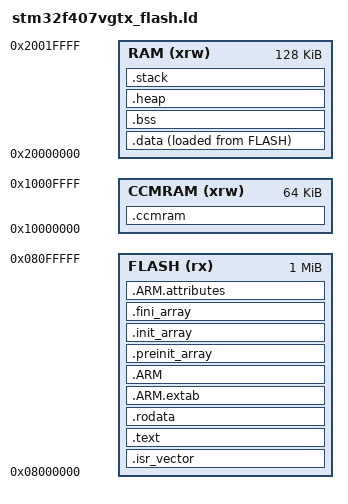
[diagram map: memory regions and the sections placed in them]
/*
 * Linker script for STM32F407VGTX (STM32F4 Discovery).
 *   FLASH: 1024 KB @ 0x08000000
 *   RAM:   128 KB @ 0x20000000
 *   CCMRAM: 64 KB @ 0x10000000
 */
ENTRY(Reset_Handler)

_estack = ORIGIN(RAM) + LENGTH(RAM);

_Min_Heap_Size = 0x200;
_Min_Stack_Size = 0x800;

MEMORY
{
  RAM    (xrw) : ORIGIN = 0x20000000, LENGTH = 128K
  CCMRAM (xrw) : ORIGIN = 0x10000000, LENGTH = 64K
  FLASH  (rx)  : ORIGIN = 0x08000000, LENGTH = 1024K
}

SECTIONS
{
  .isr_vector :
  {
    . = ALIGN(4);
    KEEP(*(.isr_vector))
    . = ALIGN(4);
  } >FLASH

  .text :
  {
    . = ALIGN(4);
    *(.text)
    *(.text*)
    *(.glue_7)
    *(.glue_7t)
    *(.eh_frame)
    KEEP(*(.init))
    KEEP(*(.fini))
    . = ALIGN(4);
    _etext = .;
  } >FLASH

  .rodata :
  {
    . = ALIGN(4);
    *(.rodata)
    *(.rodata*)
    . = ALIGN(4);
  } >FLASH

  .ARM.extab :
  {
    *(.ARM.extab* .gnu.linkonce.armextab.*)
  } >FLASH

  .ARM : {
    __exidx_start = .;
    *(.ARM.exidx*)
    __exidx_end = .;
  } >FLASH

  .preinit_array :
  {
    PROVIDE_HIDDEN(__preinit_array_start = .);
    KEEP(*(.preinit_array*))
    PROVIDE_HIDDEN(__preinit_array_end = .);
  } >FLASH

  .init_array :
  {
    PROVIDE_HIDDEN(__init_array_start = .);
    KEEP(*(SORT(.init_array.*)))
    KEEP(*(.init_array*))
    PROVIDE_HIDDEN(__init_array_end = .);
  } >FLASH

  .fini_array :
  {
    PROVIDE_HIDDEN(__fini_array_start = .);
    KEEP(*(SORT(.fini_array.*)))
    KEEP(*(.fini_array*))
    PROVIDE_HIDDEN(__fini_array_end = .);
  } >FLASH

  .ARM.attributes :
  {
    *(.ARM.attributes)
  } >FLASH

  _sidata = LOADADDR(.data);

  .data :
  {
    . = ALIGN(4);
    _sdata = .;
    *(.data)
    *(.data*)
    . = ALIGN(4);
    _edata = .;
  } >RAM AT>FLASH

  .bss :
  {
    . = ALIGN(4);
    _sbss = .;
    __bss_start__ = _sbss;
    *(.bss)
    *(.bss*)
    *(COMMON)
    . = ALIGN(4);
    _ebss = .;
    __bss_end__ = _ebss;
    end = .;
  } >RAM

  .heap (NOLOAD) :
  {
    . = ALIGN(8);
    _sheap = .;
    __heap_start = _sheap;
    . = . + _Min_Heap_Size;
    . = ALIGN(8);
    _eheap = .;
    __heap_end = _eheap;
  } >RAM

  .stack (NOLOAD) :
  {
    . = ALIGN(8);
    . = . + _Min_Stack_Size;
    . = ALIGN(8);
  } >RAM

  /* Benchmark sample sink. CCMRAM (64 KiB) is otherwise unused and has no
   * DMA path, but the sink is only written and read by the bench task, so
   * placing it here leaves the 128 KiB main RAM available for the FreeRTOS
   * heap and task stacks. */
  .ccmram (NOLOAD) :
  {
    . = ALIGN(8);
    _sccmram = .;
    *(.ccmram)
    *(.ccmram*)
    . = ALIGN(8);
    _eccmram = .;
  } >CCMRAM
}
